VERSION ""

NS_ :

BS_:

BU_:

BO_ 3221225472 VECTOR__INDEPENDENT_SIG_MSG: 0 Vector__XXX
 SG_ New_Signal_146 : 0|8@1+ (1,0) [0|0] "" Vector__XXX
 SG_ New_Signal_145 : 0|8@1+ (1,0) [0|0] "" Vector__XXX
 SG_ New_Signal_144 : 0|8@1+ (1,0) [0|0] "" Vector__XXX
 SG_ New_Signal_143 : 0|8@1+ (1,0) [0|0] "" Vector__XXX
 SG_ New_Signal_139 : 0|8@1+ (1,0) [0|0] "" Vector__XXX
 SG_ New_Signal_138 : 0|8@1+ (1,0) [0|0] "" Vector__XXX
 SG_ New_Signal_120 : 0|8@1+ (1,0) [0|0] "" Vector__XXX
 SG_ New_Signal_55 : 0|8@1+ (1,0) [0|0] "" Vector__XXX
 SG_ Delta_V : 0|16@1+ (1,0) [0|65535] "" Vector__XXX

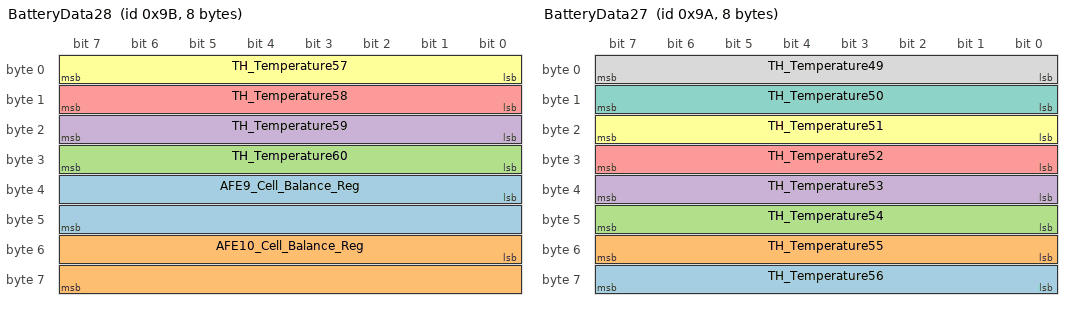
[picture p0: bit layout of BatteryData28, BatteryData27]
BO_ 155 BatteryData28: 8 Vector__XXX
 SG_ AFE9_Cell_Balance_Reg : 32|16@1+ (1,0) [0|65535] "" Vector__XXX
 SG_ AFE10_Cell_Balance_Reg : 48|16@1+ (1,0) [0|65535] "" Vector__XXX
 SG_ TH_Temperature60 : 31|8@0- (1,0) [-128|127] "degC" Vector__XXX
 SG_ TH_Temperature59 : 23|8@0- (1,0) [-128|127] "degC" Vector__XXX
 SG_ TH_Temperature58 : 15|8@0- (1,0) [-128|127] "degC" Vector__XXX
 SG_ TH_Temperature57 : 7|8@0- (1,0) [-128|127] "degC" Vector__XXX

BO_ 154 BatteryData27: 8 Vector__XXX
 SG_ TH_Temperature56 : 63|8@0- (1,0) [-128|127] "degC" Vector__XXX
 SG_ TH_Temperature55 : 55|8@0- (1,0) [-128|127] "degC" Vector__XXX
 SG_ TH_Temperature54 : 47|8@0- (1,0) [-128|127] "degC" Vector__XXX
 SG_ TH_Temperature53 : 39|8@0- (1,0) [-128|127] "degC" Vector__XXX
 SG_ TH_Temperature52 : 31|8@0- (1,0) [-128|127] "degC" Vector__XXX
 SG_ TH_Temperature51 : 23|8@0- (1,0) [-128|127] "degC" Vector__XXX
 SG_ TH_Temperature50 : 15|8@0- (1,0) [-128|127] "degC" Vector__XXX
 SG_ TH_Temperature49 : 7|8@0- (1,0) [-128|127] "degC" Vector__XXX

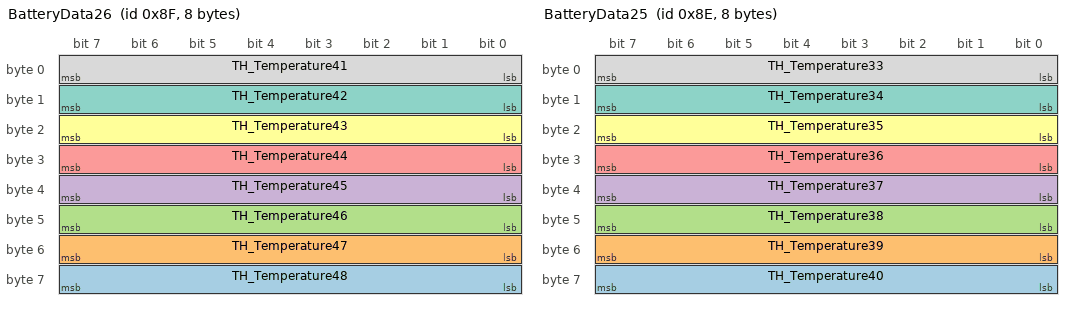
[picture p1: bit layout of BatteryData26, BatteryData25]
BO_ 143 BatteryData26: 8 Vector__XXX
 SG_ TH_Temperature48 : 63|8@0- (1,0) [-128|127] "degC" Vector__XXX
 SG_ TH_Temperature47 : 55|8@0- (1,0) [-128|127] "degC" Vector__XXX
 SG_ TH_Temperature46 : 47|8@0- (1,0) [-128|127] "degC" Vector__XXX
 SG_ TH_Temperature45 : 39|8@0- (1,0) [-128|127] "degC" Vector__XXX
 SG_ TH_Temperature44 : 31|8@0- (1,0) [-128|127] "degC" Vector__XXX
 SG_ TH_Temperature43 : 23|8@0- (1,0) [-128|127] "degC" Vector__XXX
 SG_ TH_Temperature42 : 15|8@0- (1,0) [-128|127] "degC" Vector__XXX
 SG_ TH_Temperature41 : 7|8@0- (1,0) [-128|127] "degC" Vector__XXX

BO_ 142 BatteryData25: 8 Vector__XXX
 SG_ TH_Temperature40 : 63|8@0- (1,0) [-128|127] "degC" Vector__XXX
 SG_ TH_Temperature39 : 55|8@0- (1,0) [-128|127] "degC" Vector__XXX
 SG_ TH_Temperature38 : 47|8@0- (1,0) [-128|127] "degC" Vector__XXX
 SG_ TH_Temperature37 : 39|8@0- (1,0) [-128|127] "degC" Vector__XXX
 SG_ TH_Temperature36 : 31|8@0- (1,0) [-128|127] "degC" Vector__XXX
 SG_ TH_Temperature35 : 23|8@0- (1,0) [-128|127] "degC" Vector__XXX
 SG_ TH_Temperature34 : 15|8@0- (1,0) [-128|127] "degC" Vector__XXX
 SG_ TH_Temperature33 : 7|8@0- (1,0) [-128|127] "degC" Vector__XXX

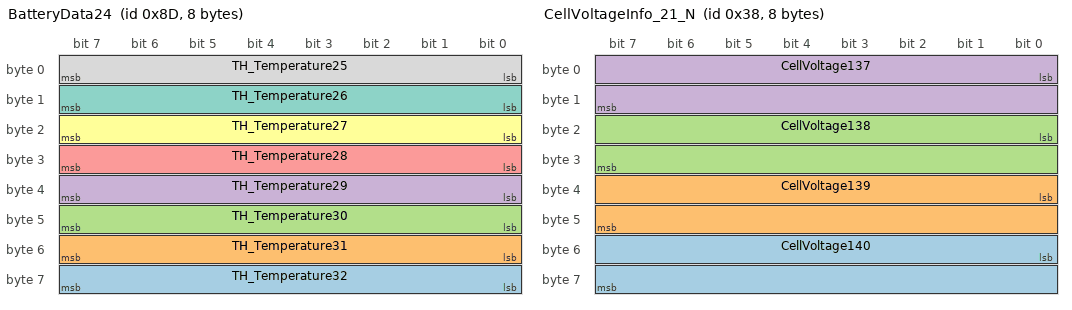
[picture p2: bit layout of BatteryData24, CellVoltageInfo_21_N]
BO_ 141 BatteryData24: 8 Vector__XXX
 SG_ TH_Temperature32 : 63|8@0- (1,0) [-128|127] "degC" Vector__XXX
 SG_ TH_Temperature31 : 55|8@0- (1,0) [-128|127] "degC" Vector__XXX
 SG_ TH_Temperature30 : 47|8@0- (1,0) [-128|127] "degC" Vector__XXX
 SG_ TH_Temperature29 : 39|8@0- (1,0) [-128|127] "degC" Vector__XXX
 SG_ TH_Temperature28 : 31|8@0- (1,0) [-128|127] "degC" Vector__XXX
 SG_ TH_Temperature27 : 23|8@0- (1,0) [-128|127] "degC" Vector__XXX
 SG_ TH_Temperature26 : 15|8@0- (1,0) [-128|127] "degC" Vector__XXX
 SG_ TH_Temperature25 : 7|8@0- (1,0) [-128|127] "degC" Vector__XXX

BO_ 56 CellVoltageInfo_21_N: 8 Vector__XXX
 SG_ CellVoltage140 : 48|16@1+ (0.001,0) [2.7|4.2] "V" Vector__XXX
 SG_ CellVoltage139 : 32|16@1+ (0.001,0) [2.7|4.2] "V" Vector__XXX
 SG_ CellVoltage138 : 16|16@1+ (0.001,0) [2.7|4.2] "V" Vector__XXX
 SG_ CellVoltage137 : 0|16@1+ (0.001,0) [2.7|4.2] "V" Vector__XXX

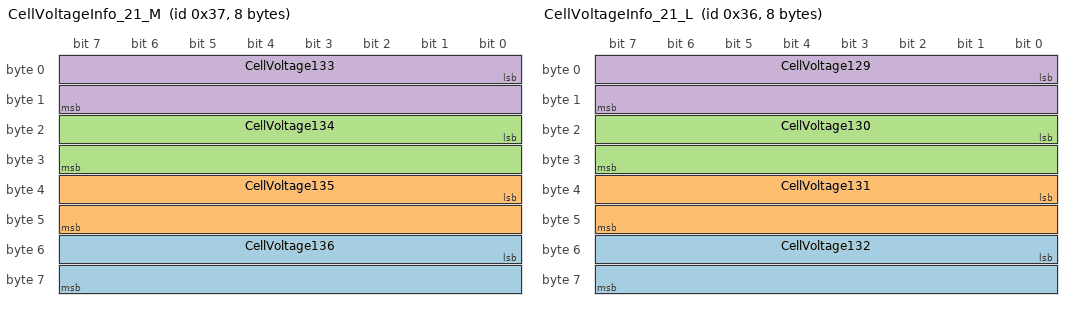
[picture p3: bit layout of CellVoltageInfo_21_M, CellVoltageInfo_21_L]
BO_ 55 CellVoltageInfo_21_M: 8 Vector__XXX
 SG_ CellVoltage136 : 48|16@1+ (0.001,0) [2.7|4.2] "V" Vector__XXX
 SG_ CellVoltage135 : 32|16@1+ (0.001,0) [2.7|4.2] "V" Vector__XXX
 SG_ CellVoltage134 : 16|16@1+ (0.001,0) [2.7|4.2] "V" Vector__XXX
 SG_ CellVoltage133 : 0|16@1+ (0.001,0) [2.7|4.2] "V" Vector__XXX

BO_ 54 CellVoltageInfo_21_L: 8 Vector__XXX
 SG_ CellVoltage132 : 48|16@1+ (0.001,0) [2.7|4.2] "V" Vector__XXX
 SG_ CellVoltage131 : 32|16@1+ (0.001,0) [2.7|4.2] "V" Vector__XXX
 SG_ CellVoltage130 : 16|16@1+ (0.001,0) [2.7|4.2] "V" Vector__XXX
 SG_ CellVoltage129 : 0|16@1+ (0.001,0) [2.7|4.2] "V" Vector__XXX

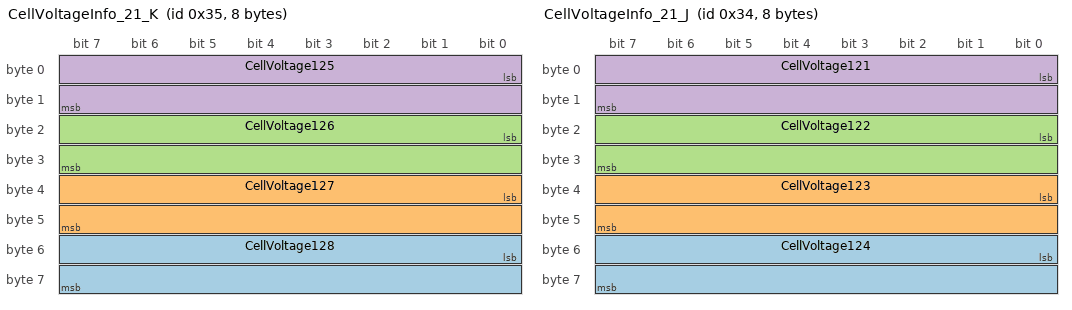
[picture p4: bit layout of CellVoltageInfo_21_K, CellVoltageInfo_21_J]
BO_ 53 CellVoltageInfo_21_K: 8 Vector__XXX
 SG_ CellVoltage128 : 48|16@1+ (0.001,0) [2.7|4.2] "V" Vector__XXX
 SG_ CellVoltage127 : 32|16@1+ (0.001,0) [2.7|4.2] "V" Vector__XXX
 SG_ CellVoltage126 : 16|16@1+ (0.001,0) [2.7|4.2] "V" Vector__XXX
 SG_ CellVoltage125 : 0|16@1+ (0.001,0) [2.7|4.2] "V" Vector__XXX

BO_ 52 CellVoltageInfo_21_J: 8 Vector__XXX
 SG_ CellVoltage124 : 48|16@1+ (0.001,0) [2.7|4.2] "V" Vector__XXX
 SG_ CellVoltage123 : 32|16@1+ (0.001,0) [2.7|4.2] "V" Vector__XXX
 SG_ CellVoltage122 : 16|16@1+ (0.001,0) [2.7|4.2] "V" Vector__XXX
 SG_ CellVoltage121 : 0|16@1+ (0.001,0) [2.7|4.2] "V" Vector__XXX

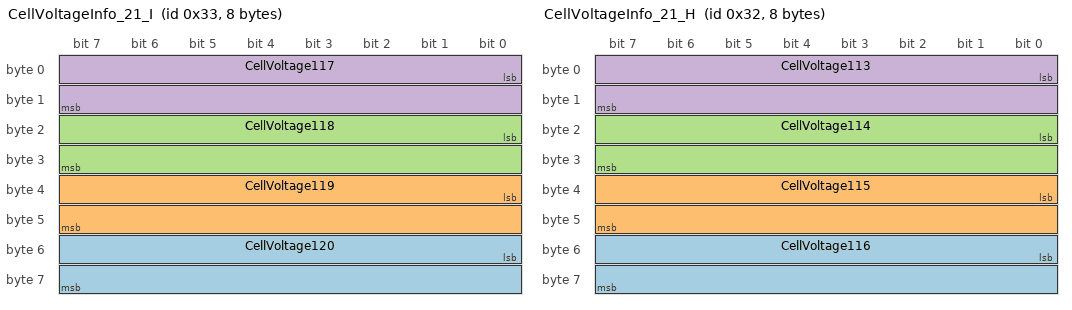
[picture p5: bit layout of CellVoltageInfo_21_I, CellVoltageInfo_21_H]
BO_ 51 CellVoltageInfo_21_I: 8 Vector__XXX
 SG_ CellVoltage120 : 48|16@1+ (0.001,0) [2.7|4.2] "V" Vector__XXX
 SG_ CellVoltage119 : 32|16@1+ (0.001,0) [2.7|4.2] "V" Vector__XXX
 SG_ CellVoltage118 : 16|16@1+ (0.001,0) [2.7|4.2] "V" Vector__XXX
 SG_ CellVoltage117 : 0|16@1+ (0.001,0) [2.7|4.2] "V" Vector__XXX

BO_ 50 CellVoltageInfo_21_H: 8 Vector__XXX
 SG_ CellVoltage116 : 48|16@1+ (0.001,0) [2.7|4.2] "V" Vector__XXX
 SG_ CellVoltage115 : 32|16@1+ (0.001,0) [2.7|4.2] "V" Vector__XXX
 SG_ CellVoltage114 : 16|16@1+ (0.001,0) [2.7|4.2] "V" Vector__XXX
 SG_ CellVoltage113 : 0|16@1+ (0.001,0) [2.7|4.2] "V" Vector__XXX

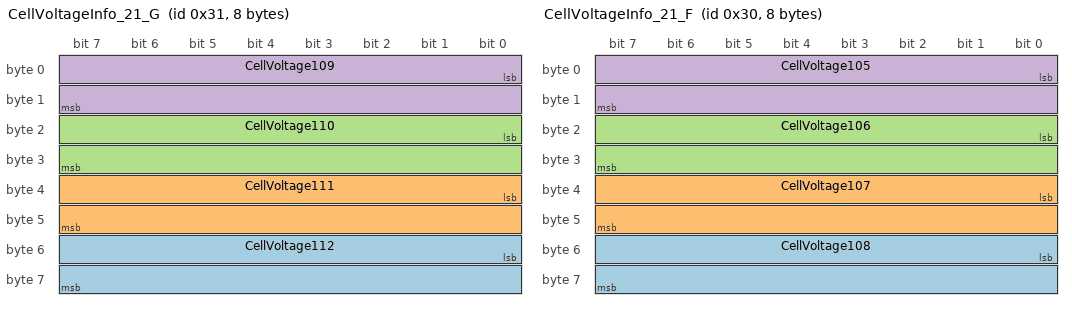
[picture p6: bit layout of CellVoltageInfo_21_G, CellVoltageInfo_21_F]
BO_ 49 CellVoltageInfo_21_G: 8 Vector__XXX
 SG_ CellVoltage112 : 48|16@1+ (0.001,0) [2.7|4.2] "V" Vector__XXX
 SG_ CellVoltage111 : 32|16@1+ (0.001,0) [2.7|4.2] "V" Vector__XXX
 SG_ CellVoltage110 : 16|16@1+ (0.001,0) [2.7|4.2] "V" Vector__XXX
 SG_ CellVoltage109 : 0|16@1+ (0.001,0) [2.7|4.2] "V" Vector__XXX

BO_ 48 CellVoltageInfo_21_F: 8 Vector__XXX
 SG_ CellVoltage108 : 48|16@1+ (0.001,0) [2.7|4.2] "V" Vector__XXX
 SG_ CellVoltage107 : 32|16@1+ (0.001,0) [2.7|4.2] "V" Vector__XXX
 SG_ CellVoltage106 : 16|16@1+ (0.001,0) [2.7|4.2] "V" Vector__XXX
 SG_ CellVoltage105 : 0|16@1+ (0.001,0) [2.7|4.2] "V" Vector__XXX

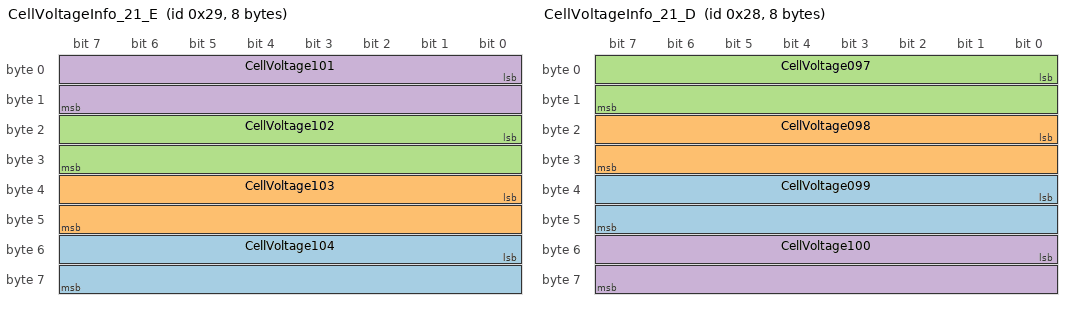
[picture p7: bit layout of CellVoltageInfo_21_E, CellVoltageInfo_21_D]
BO_ 41 CellVoltageInfo_21_E: 8 Vector__XXX
 SG_ CellVoltage104 : 48|16@1+ (0.001,0) [2.7|4.2] "V" Vector__XXX
 SG_ CellVoltage103 : 32|16@1+ (0.001,0) [2.7|4.2] "V" Vector__XXX
 SG_ CellVoltage102 : 16|16@1+ (0.001,0) [2.7|4.2] "V" Vector__XXX
 SG_ CellVoltage101 : 0|16@1+ (0.001,0) [2.7|4.2] "V" Vector__XXX

BO_ 40 CellVoltageInfo_21_D: 8 Vector__XXX
 SG_ CellVoltage099 : 32|16@1+ (0.001,0) [2.7|4.2] "V" Vector__XXX
 SG_ CellVoltage098 : 16|16@1+ (0.001,0) [2.7|4.2] "V" Vector__XXX
 SG_ CellVoltage097 : 0|16@1+ (0.001,0) [2.7|4.2] "V" Vector__XXX
 SG_ CellVoltage100 : 48|16@1+ (0.001,0) [2.7|4.2] "V" Vector__XXX

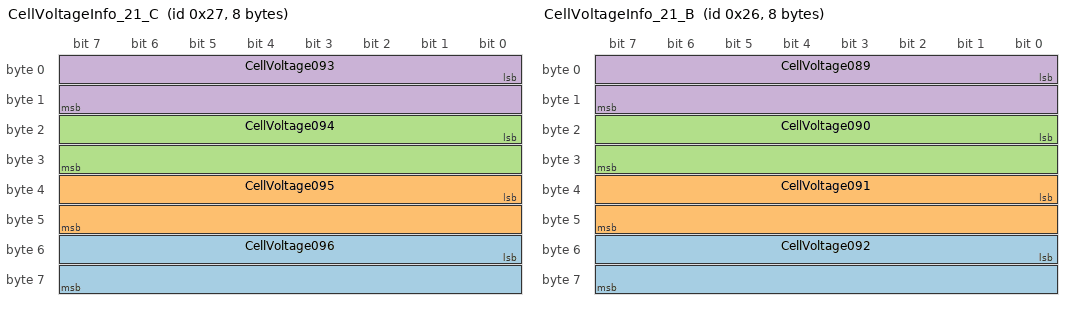
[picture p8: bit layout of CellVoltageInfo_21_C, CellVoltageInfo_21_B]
BO_ 39 CellVoltageInfo_21_C: 8 Vector__XXX
 SG_ CellVoltage096 : 48|16@1+ (0.001,0) [2.7|4.2] "V" Vector__XXX
 SG_ CellVoltage095 : 32|16@1+ (0.001,0) [2.7|4.2] "V" Vector__XXX
 SG_ CellVoltage094 : 16|16@1+ (0.001,0) [2.7|4.2] "V" Vector__XXX
 SG_ CellVoltage093 : 0|16@1+ (0.001,0) [2.7|4.2] "V" Vector__XXX

BO_ 38 CellVoltageInfo_21_B: 8 Vector__XXX
 SG_ CellVoltage092 : 48|16@1+ (0.001,0) [2.7|4.2] "V" Vector__XXX
 SG_ CellVoltage091 : 32|16@1+ (0.001,0) [2.7|4.2] "V" Vector__XXX
 SG_ CellVoltage090 : 16|16@1+ (0.001,0) [2.7|4.2] "V" Vector__XXX
 SG_ CellVoltage089 : 0|16@1+ (0.001,0) [2.7|4.2] "V" Vector__XXX

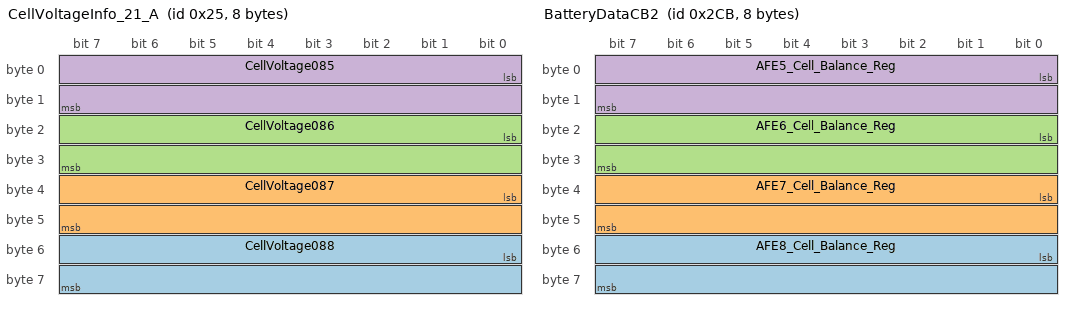
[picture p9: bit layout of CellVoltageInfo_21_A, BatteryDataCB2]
BO_ 37 CellVoltageInfo_21_A: 8 Vector__XXX
 SG_ CellVoltage088 : 48|16@1+ (0.001,0) [2.7|4.2] "V" Vector__XXX
 SG_ CellVoltage087 : 32|16@1+ (0.001,0) [2.7|4.2] "V" Vector__XXX
 SG_ CellVoltage086 : 16|16@1+ (0.001,0) [2.7|4.2] "V" Vector__XXX
 SG_ CellVoltage085 : 0|16@1+ (0.001,0) [2.7|4.2] "V" Vector__XXX

BO_ 715 BatteryDataCB2: 8 Vector__XXX
 SG_ AFE8_Cell_Balance_Reg : 48|16@1+ (1,0) [0|65535] "" Vector__XXX
 SG_ AFE7_Cell_Balance_Reg : 32|16@1+ (1,0) [0|65535] "" Vector__XXX
 SG_ AFE6_Cell_Balance_Reg : 16|16@1+ (1,0) [0|65535] "" Vector__XXX
 SG_ AFE5_Cell_Balance_Reg : 0|16@1+ (1,0) [0|65535] "" Vector__XXX

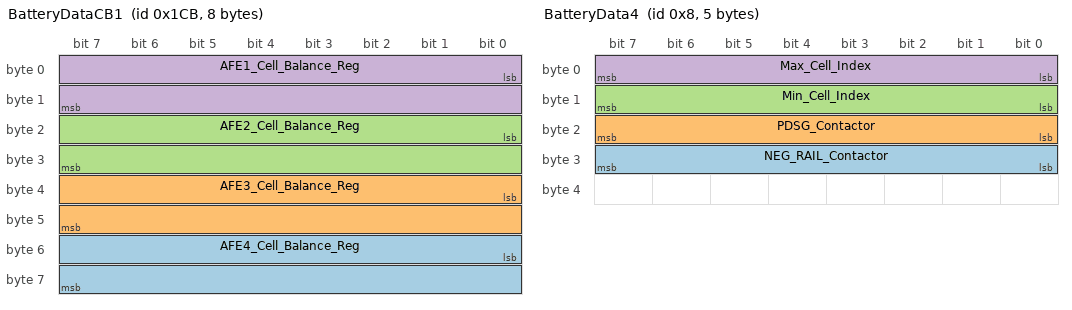
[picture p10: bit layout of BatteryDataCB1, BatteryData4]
BO_ 459 BatteryDataCB1: 8 Vector__XXX
 SG_ AFE4_Cell_Balance_Reg : 48|16@1+ (1,0) [0|65535] "" Vector__XXX
 SG_ AFE3_Cell_Balance_Reg : 32|16@1+ (1,0) [0|65535] "" Vector__XXX
 SG_ AFE2_Cell_Balance_Reg : 16|16@1+ (1,0) [0|65535] "" Vector__XXX
 SG_ AFE1_Cell_Balance_Reg : 0|16@1+ (1,0) [0|65535] "" Vector__XXX

BO_ 8 BatteryData4: 5 Vector__XXX
 SG_ NEG_RAIL_Contactor : 24|8@1+ (1,0) [0|1] "" Vector__XXX
 SG_ PDSG_Contactor : 16|8@1+ (1,0) [0|1] "" Vector__XXX
 SG_ Min_Cell_Index : 8|8@1+ (1,0) [0|100] "" Vector__XXX
 SG_ Max_Cell_Index : 0|8@1+ (1,0) [0|100] "" Vector__XXX

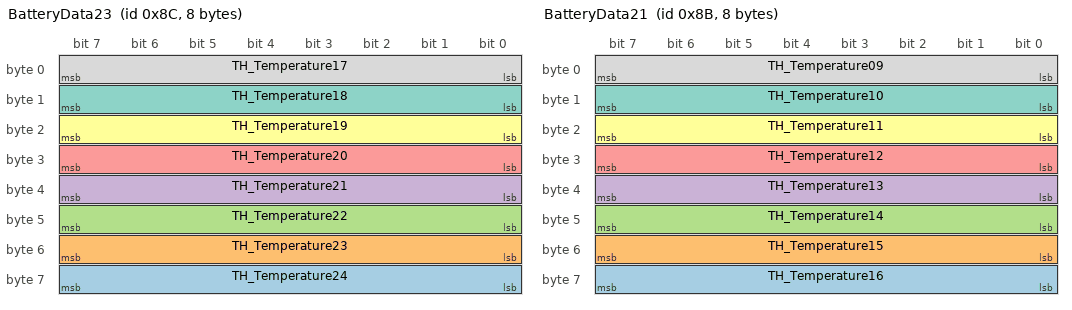
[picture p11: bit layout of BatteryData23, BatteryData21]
BO_ 140 BatteryData23: 8 Vector__XXX
 SG_ TH_Temperature24 : 63|8@0- (1,0) [-128|127] "degC" Vector__XXX
 SG_ TH_Temperature23 : 55|8@0- (1,0) [-128|127] "degC" Vector__XXX
 SG_ TH_Temperature22 : 47|8@0- (1,0) [-128|127] "degC" Vector__XXX
 SG_ TH_Temperature21 : 39|8@0- (1,0) [-128|127] "degC" Vector__XXX
 SG_ TH_Temperature20 : 31|8@0- (1,0) [-128|127] "degC" Vector__XXX
 SG_ TH_Temperature19 : 23|8@0- (1,0) [-128|127] "degC" Vector__XXX
 SG_ TH_Temperature18 : 15|8@0- (1,0) [-128|127] "degC" Vector__XXX
 SG_ TH_Temperature17 : 7|8@0- (1,0) [-128|127] "degC" Vector__XXX

BO_ 139 BatteryData21: 8 Vector__XXX
 SG_ TH_Temperature16 : 63|8@0- (1,0) [-128|127] "degC" Vector__XXX
 SG_ TH_Temperature15 : 55|8@0- (1,0) [-128|127] "degC" Vector__XXX
 SG_ TH_Temperature14 : 47|8@0- (1,0) [-128|127] "degC" Vector__XXX
 SG_ TH_Temperature13 : 39|8@0- (1,0) [-128|127] "degC" Vector__XXX
 SG_ TH_Temperature12 : 24|8@1- (1,0) [-128|127] "degC" Vector__XXX
 SG_ TH_Temperature11 : 23|8@0- (1,0) [-128|127] "degC" Vector__XXX
 SG_ TH_Temperature10 : 15|8@0- (1,0) [-128|127] "degC" Vector__XXX
 SG_ TH_Temperature09 : 7|8@0- (1,0) [-128|127] "degC" Vector__XXX

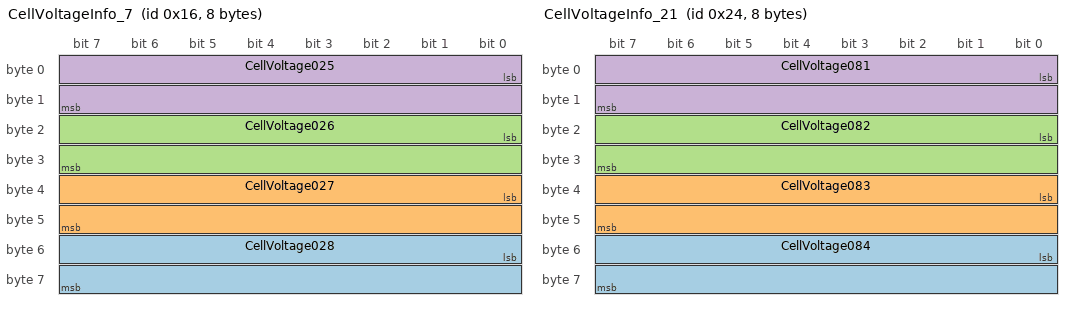
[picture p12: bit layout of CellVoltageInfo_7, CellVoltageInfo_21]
BO_ 22 CellVoltageInfo_7: 8 Vector__XXX
 SG_ CellVoltage028 : 48|16@1+ (0.001,0) [2.7|4.2] "V" Vector__XXX
 SG_ CellVoltage027 : 32|16@1+ (0.001,0) [2.7|4.2] "V" Vector__XXX
 SG_ CellVoltage026 : 16|16@1+ (0.001,0) [2.7|4.2] "V" Vector__XXX
 SG_ CellVoltage025 : 0|16@1+ (0.001,0) [2.7|4.2] "V" Vector__XXX

BO_ 36 CellVoltageInfo_21: 8 Vector__XXX
 SG_ CellVoltage084 : 48|16@1+ (0.001,0) [2.7|4.2] "V" Vector__XXX
 SG_ CellVoltage083 : 32|16@1+ (0.001,0) [2.7|4.2] "V" Vector__XXX
 SG_ CellVoltage082 : 16|16@1+ (0.001,0) [2.7|4.2] "V" Vector__XXX
 SG_ CellVoltage081 : 0|16@1+ (0.001,0) [2.7|4.2] "V" Vector__XXX

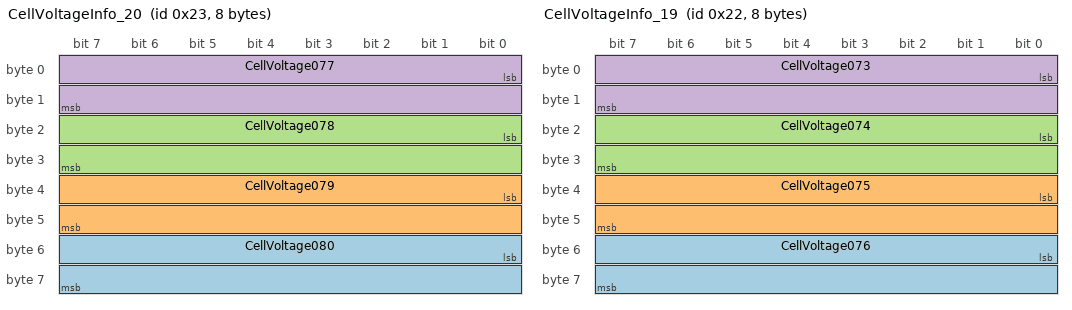
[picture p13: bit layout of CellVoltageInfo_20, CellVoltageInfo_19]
BO_ 35 CellVoltageInfo_20: 8 Vector__XXX
 SG_ CellVoltage080 : 48|16@1+ (0.001,0) [2.7|4.2] "V" Vector__XXX
 SG_ CellVoltage079 : 32|16@1+ (0.001,0) [2.7|4.2] "V" Vector__XXX
 SG_ CellVoltage078 : 16|16@1+ (0.001,0) [2.7|4.2] "V" Vector__XXX
 SG_ CellVoltage077 : 0|16@1+ (0.001,0) [2.7|4.2] "V" Vector__XXX

BO_ 34 CellVoltageInfo_19: 8 Vector__XXX
 SG_ CellVoltage076 : 48|16@1+ (0.001,0) [2.7|4.2] "V" Vector__XXX
 SG_ CellVoltage075 : 32|16@1+ (0.001,0) [2.7|4.2] "V" Vector__XXX
 SG_ CellVoltage074 : 16|16@1+ (0.001,0) [2.7|4.2] "V" Vector__XXX
 SG_ CellVoltage073 : 0|16@1+ (0.001,0) [2.7|4.2] "V" Vector__XXX

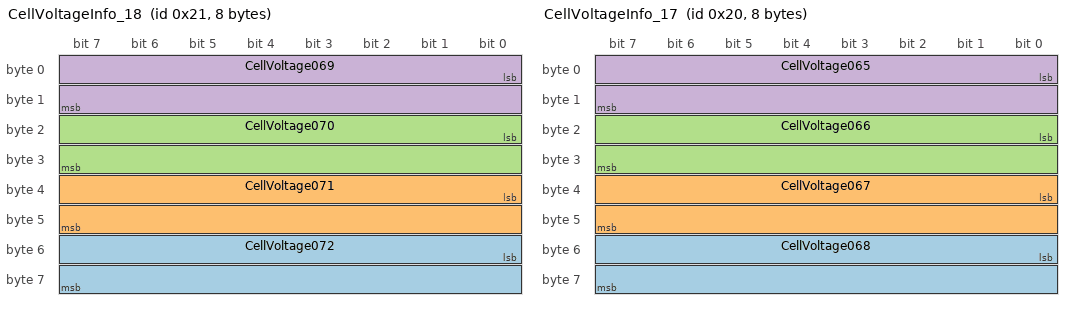
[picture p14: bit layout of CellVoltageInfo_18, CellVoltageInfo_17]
BO_ 33 CellVoltageInfo_18: 8 Vector__XXX
 SG_ CellVoltage072 : 48|16@1+ (0.001,0) [2.7|4.2] "V" Vector__XXX
 SG_ CellVoltage071 : 32|16@1+ (0.001,0) [2.7|4.2] "V" Vector__XXX
 SG_ CellVoltage070 : 16|16@1+ (0.001,0) [2.7|4.2] "V" Vector__XXX
 SG_ CellVoltage069 : 0|16@1+ (0.001,0) [2.7|4.2] "V" Vector__XXX

BO_ 32 CellVoltageInfo_17: 8 Vector__XXX
 SG_ CellVoltage068 : 48|16@1+ (0.001,0) [2.7|4.2] "V" Vector__XXX
 SG_ CellVoltage067 : 32|16@1+ (0.001,0) [2.7|4.2] "V" Vector__XXX
 SG_ CellVoltage066 : 16|16@1+ (0.001,0) [2.7|4.2] "V" Vector__XXX
 SG_ CellVoltage065 : 0|16@1+ (0.001,0) [2.7|4.2] "V" Vector__XXX

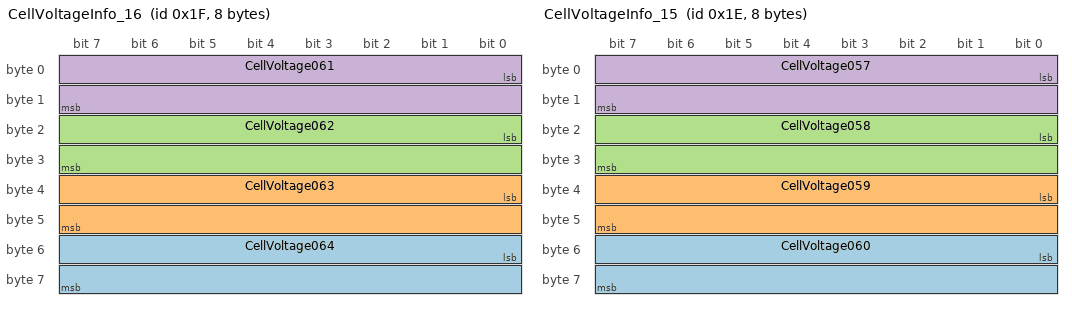
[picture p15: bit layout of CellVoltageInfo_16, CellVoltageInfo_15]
BO_ 31 CellVoltageInfo_16: 8 Vector__XXX
 SG_ CellVoltage064 : 48|16@1+ (0.001,0) [2.7|4.2] "V" Vector__XXX
 SG_ CellVoltage063 : 32|16@1+ (0.001,0) [2.7|4.2] "V" Vector__XXX
 SG_ CellVoltage062 : 16|16@1+ (0.001,0) [2.7|4.2] "V" Vector__XXX
 SG_ CellVoltage061 : 0|16@1+ (0.001,0) [2.7|4.2] "V" Vector__XXX

BO_ 30 CellVoltageInfo_15: 8 Vector__XXX
 SG_ CellVoltage060 : 48|16@1+ (0.001,0) [2.7|4.2] "V" Vector__XXX
 SG_ CellVoltage059 : 32|16@1+ (0.001,0) [2.7|4.2] "V" Vector__XXX
 SG_ CellVoltage058 : 16|16@1+ (0.001,0) [2.7|4.2] "V" Vector__XXX
 SG_ CellVoltage057 : 0|16@1+ (0.001,0) [2.7|4.2] "V" Vector__XXX

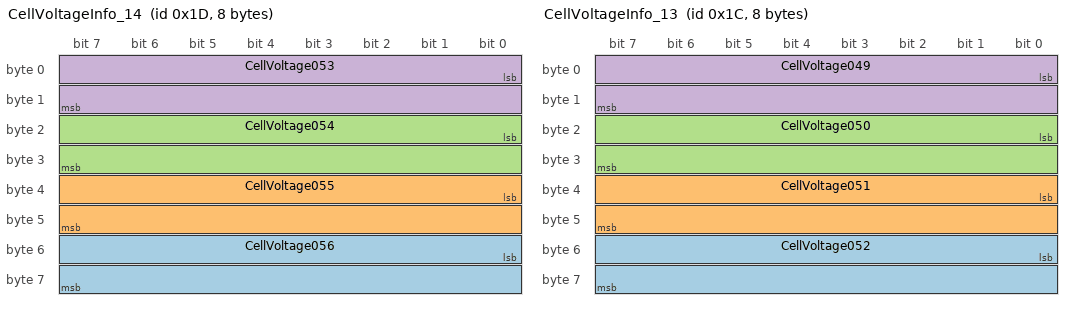
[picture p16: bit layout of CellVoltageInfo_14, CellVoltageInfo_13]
BO_ 29 CellVoltageInfo_14: 8 Vector__XXX
 SG_ CellVoltage056 : 48|16@1+ (0.001,0) [2.7|4.2] "V" Vector__XXX
 SG_ CellVoltage055 : 32|16@1+ (0.001,0) [2.7|4.2] "V" Vector__XXX
 SG_ CellVoltage054 : 16|16@1+ (0.001,0) [2.7|4.2] "V" Vector__XXX
 SG_ CellVoltage053 : 0|16@1+ (0.001,0) [2.7|4.2] "V" Vector__XXX

BO_ 28 CellVoltageInfo_13: 8 Vector__XXX
 SG_ CellVoltage052 : 48|16@1+ (0.001,0) [2.7|4.2] "V" Vector__XXX
 SG_ CellVoltage051 : 32|16@1+ (0.001,0) [2.7|4.2] "V" Vector__XXX
 SG_ CellVoltage050 : 16|16@1+ (0.001,0) [2.7|4.2] "V" Vector__XXX
 SG_ CellVoltage049 : 0|16@1+ (0.001,0) [2.7|4.2] "V" Vector__XXX

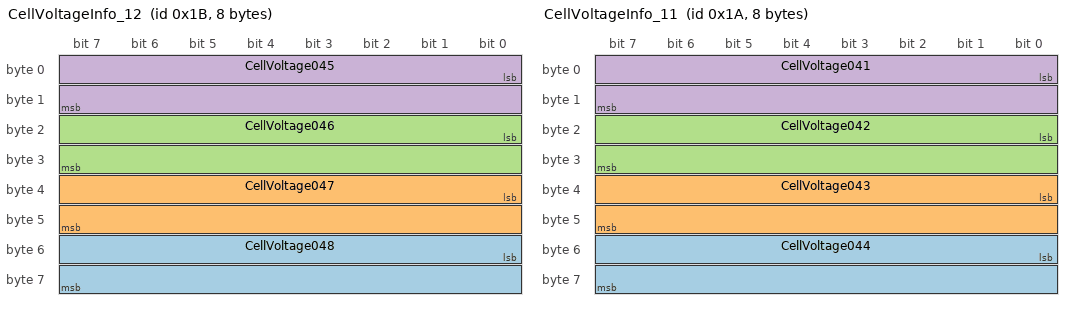
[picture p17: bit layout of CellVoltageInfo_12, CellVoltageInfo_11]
BO_ 27 CellVoltageInfo_12: 8 Vector__XXX
 SG_ CellVoltage048 : 48|16@1+ (0.001,0) [2.7|4.2] "V" Vector__XXX
 SG_ CellVoltage047 : 32|16@1+ (0.001,0) [2.7|4.2] "V" Vector__XXX
 SG_ CellVoltage046 : 16|16@1+ (0.001,0) [2.7|4.2] "V" Vector__XXX
 SG_ CellVoltage045 : 0|16@1+ (0.001,0) [2.7|4.2] "V" Vector__XXX

BO_ 26 CellVoltageInfo_11: 8 Vector__XXX
 SG_ CellVoltage044 : 48|16@1+ (0.001,0) [2.7|4.2] "V" Vector__XXX
 SG_ CellVoltage043 : 32|16@1+ (0.001,0) [2.7|4.2] "V" Vector__XXX
 SG_ CellVoltage042 : 16|16@1+ (0.001,0) [2.7|4.2] "V" Vector__XXX
 SG_ CellVoltage041 : 0|16@1+ (0.001,0) [2.7|4.2] "V" Vector__XXX

BO_ 25 CellVoltageInfo_10: 8 Vector__XXX
 SG_ CellVoltage040 : 48|16@1+ (0.001,0) [2.7|4.2] "V" Vector__XXX
 SG_ CellVoltage039 : 32|16@1+ (0.001,0) [2.7|4.2] "V" Vector__XXX
 SG_ CellVoltage038 : 16|16@1+ (0.001,0) [2.7|4.2] "V" Vector__XXX
 SG_ CellVoltage037 : 0|16@1+ (0.001,0) [2.7|4.2] "V" Vector__XXX

BO_ 24 CellVoltageInfo_9: 8 Vector__XXX
 SG_ CellVoltage036 : 48|16@1+ (0.001,0) [2.7|4.2] "V" Vector__XXX
 SG_ CellVoltage035 : 32|16@1+ (0.001,0) [2.7|4.2] "V" Vector__XXX
 SG_ CellVoltage034 : 16|16@1+ (0.001,0) [2.7|4.2] "V" Vector__XXX
 SG_ CellVoltage033 : 0|16@1+ (0.001,0) [2.7|4.2] "V" Vector__XXX

BO_ 23 CellVoltageInfo_8: 8 Vector__XXX
 SG_ CellVoltage032 : 48|16@1+ (0.001,0) [2.7|4.2] "V" Vector__XXX
 SG_ CellVoltage031 : 32|16@1+ (0.001,0) [2.7|4.2] "V" Vector__XXX
 SG_ CellVoltage030 : 16|16@1+ (0.001,0) [2.7|4.2] "V" Vector__XXX
 SG_ CellVoltage029 : 0|16@1+ (0.001,0) [2.7|4.2] "V" Vector__XXX

BO_ 21 CellVoltageInfo_6: 8 Vector__XXX
 SG_ CellVoltage024 : 48|16@1+ (0.001,0) [2.7|4.2] "V" Vector__XXX
 SG_ CellVoltage023 : 32|16@1+ (0.001,0) [2.7|4.2] "V" Vector__XXX
 SG_ CellVoltage022 : 16|16@1+ (0.001,0) [2.7|4.2] "V" Vector__XXX
 SG_ CellVoltage021 : 0|16@1+ (0.001,0) [2.7|4.2] "V" Vector__XXX

BO_ 20 CellVoltageInfo_5: 8 Vector__XXX
 SG_ CellVoltage020 : 48|16@1+ (0.001,0) [2.7|4.2] "V" Vector__XXX
 SG_ CellVoltage019 : 32|16@1+ (0.001,0) [2.7|4.2] "V" Vector__XXX
 SG_ CellVoltage018 : 16|16@1+ (0.001,0) [2.7|4.2] "V" Vector__XXX
 SG_ CellVoltage017 : 0|16@1+ (0.001,0) [2.7|4.2] "V" Vector__XXX

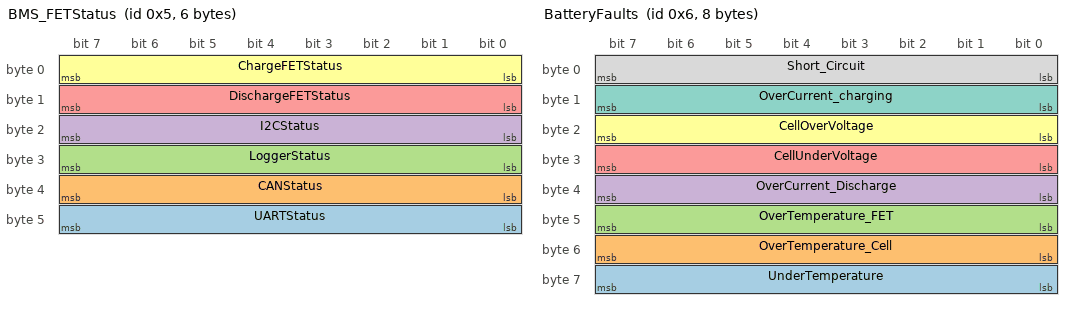
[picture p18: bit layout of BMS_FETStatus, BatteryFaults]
BO_ 5 BMS_FETStatus: 6 Vector__XXX
 SG_ UARTStatus : 47|8@0+ (1,0) [0|0] "" Vector__XXX
 SG_ CANStatus : 39|8@0+ (1,0) [0|0] "" Vector__XXX
 SG_ LoggerStatus : 31|8@0+ (1,0) [0|0] "" Vector__XXX
 SG_ I2CStatus : 23|8@0+ (1,0) [0|0] "" Vector__XXX
 SG_ DischargeFETStatus : 15|8@0+ (1,0) [0|1] "" Vector__XXX
 SG_ ChargeFETStatus : 0|8@1+ (1,0) [0|1] "" Vector__XXX

BO_ 6 BatteryFaults: 8 Vector__XXX
 SG_ UnderTemperature : 63|8@0+ (1,0) [0|0] "" Vector__XXX
 SG_ OverTemperature_Cell : 55|8@0+ (1,0) [0|0] "" Vector__XXX
 SG_ OverTemperature_FET : 47|8@0+ (1,0) [0|0] "" Vector__XXX
 SG_ OverCurrent_Discharge : 39|8@0+ (1,0) [0|0] "" Vector__XXX
 SG_ CellUnderVoltage : 31|8@0+ (1,0) [0|0] "" Vector__XXX
 SG_ CellOverVoltage : 23|8@0+ (1,0) [0|0] "" Vector__XXX
 SG_ OverCurrent_charging : 15|8@0+ (1,0) [0|0] "" Vector__XXX
 SG_ Short_Circuit : 7|8@0+ (1,0) [0|0] "" Vector__XXX

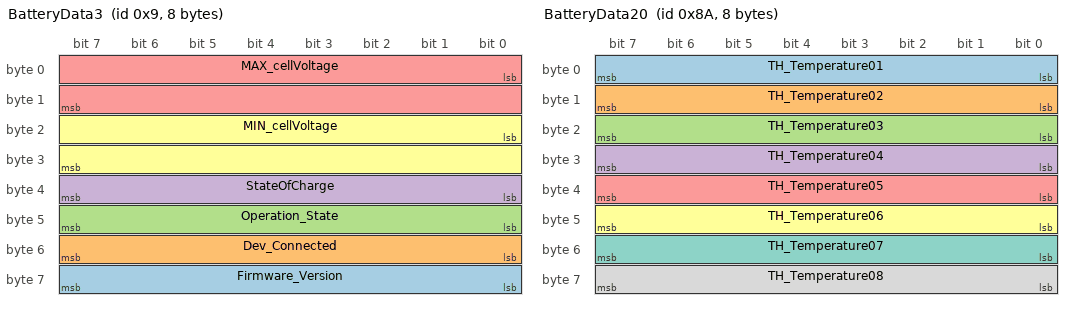
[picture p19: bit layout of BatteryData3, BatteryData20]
BO_ 9 BatteryData3: 8 Vector__XXX
 SG_ Firmware_Version : 56|8@1+ (1,0) [0|255] "" Vector__XXX
 SG_ Dev_Connected : 48|8@1+ (1,0) [0|10] "" Vector__XXX
 SG_ Operation_State : 40|8@1- (1,0) [0|3] "" Vector__XXX
 SG_ StateOfCharge : 32|8@1- (1,0) [0|100] "%" Vector__XXX
 SG_ MAX_cellVoltage : 0|16@1+ (0.001,0) [0|65.535] "V" Vector__XXX
 SG_ MIN_cellVoltage : 16|16@1+ (0.001,0) [0|65.535] "V" Vector__XXX

BO_ 138 BatteryData20: 8 Vector__XXX
 SG_ TH_Temperature01 : 7|8@0+ (1,0) [-128|127] "" Vector__XXX
 SG_ TH_Temperature02 : 15|8@0- (1,0) [-128|127] "degC" Vector__XXX
 SG_ TH_Temperature03 : 23|8@0- (1,0) [-128|127] "degC" Vector__XXX
 SG_ TH_Temperature04 : 31|8@0- (1,0) [-128|127] "degC" Vector__XXX
 SG_ TH_Temperature05 : 39|8@0- (1,0) [-128|127] "degC" Vector__XXX
 SG_ TH_Temperature06 : 47|8@0- (1,0) [-128|127] "degC" Vector__XXX
 SG_ TH_Temperature07 : 55|8@0- (1,0) [-128|127] "degC" Vector__XXX
 SG_ TH_Temperature08 : 63|8@0- (1,0) [-128|127] "degC" Vector__XXX

BO_ 7 BatteryData1: 8 Vector__XXX
 SG_ Cycle_Count : 48|16@1- (1,0) [0|5000] "" Vector__XXX
 SG_ BatteryCapacity : 32|16@1- (1,0) [0|45] "Ah" Vector__XXX
 SG_ Pack_voltage : 16|16@1+ (0.01,0) [0|90] "Volt" Vector__XXX
 SG_ PackCurrent : 0|16@1- (1,0) [-327.68|327.67] "A" Vector__XXX

BO_ 19 CellVoltageInfo_4: 8 Vector__XXX
 SG_ CellVoltage016 : 48|16@1+ (0.001,0) [2.7|4.2] "V" Vector__XXX
 SG_ CellVoltage015 : 32|16@1+ (0.001,0) [2.7|4.2] "V" Vector__XXX
 SG_ CellVoltage014 : 16|16@1+ (0.001,0) [2.7|4.2] "V" Vector__XXX
 SG_ CellVoltage013 : 0|16@1+ (0.001,0) [2.7|4.2] "V" Vector__XXX

BO_ 18 CellVoltageInfo_3: 8 Vector__XXX
 SG_ CellVoltage012 : 48|16@1+ (0.001,0) [2.7|4.2] "V" Vector__XXX
 SG_ CellVoltage011 : 32|16@1+ (0.001,0) [2.7|4.2] "V" Vector__XXX
 SG_ CellVoltage010 : 16|16@1+ (0.001,0) [2.7|4.2] "V" Vector__XXX
 SG_ CellVoltage009 : 0|16@1+ (0.001,0) [2.7|4.2] "V" Vector__XXX

BO_ 17 CellVoltageInfo_2: 8 Vector__XXX
 SG_ CellVoltage008 : 48|16@1+ (0.001,0) [2.7|4.2] "V" Vector__XXX
 SG_ CellVoltage007 : 32|16@1+ (0.001,0) [2.7|4.2] "V" Vector__XXX
 SG_ CellVoltage006 : 16|16@1+ (0.001,0) [2.7|4.2] "V" Vector__XXX
 SG_ CellVoltage005 : 0|16@1+ (0.001,0) [2.7|4.2] "V" Vector__XXX

BO_ 16 CellVoltageInfo_1: 8 Vector__XXX
 SG_ CellVoltage004 : 48|16@1+ (0.001,0) [2.7|4.2] "V" Vector__XXX
 SG_ CellVoltage003 : 32|16@1+ (0.001,0) [2.7|4.2] "V" Vector__XXX
 SG_ CellVoltage002 : 16|16@1+ (0.001,0) [2.7|4.2] "V" Vector__XXX
 SG_ CellVoltage001 : 0|16@1+ (0.001,0) [2.7|4.2] "V" Vector__XXX

CM_ BO_ 3221225472 "This is a message for not used signals, created by Vector CANdb++ DBC OLE DB Provider.";
CM_ SG_ 56 CellVoltage140 "16 bit voltage value of cell 16";
CM_ SG_ 56 CellVoltage139 "16 bit voltage value of cell 16";
CM_ SG_ 56 CellVoltage138 "16 bit voltage value of cell 16";
CM_ SG_ 56 CellVoltage137 "16 bit voltage value of cell 16";
CM_ SG_ 55 CellVoltage136 "16 bit voltage value of cell 16";
CM_ SG_ 55 CellVoltage135 "16 bit voltage value of cell 16";
CM_ SG_ 55 CellVoltage134 "16 bit voltage value of cell 16";
CM_ SG_ 55 CellVoltage133 "16 bit voltage value of cell 16";
CM_ SG_ 54 CellVoltage132 "16 bit voltage value of cell 16";
CM_ SG_ 54 CellVoltage131 "16 bit voltage value of cell 16";
CM_ SG_ 54 CellVoltage130 "16 bit voltage value of cell 16";
CM_ SG_ 54 CellVoltage129 "16 bit voltage value of cell 16";
CM_ SG_ 53 CellVoltage128 "16 bit voltage value of cell 16";
CM_ SG_ 53 CellVoltage127 "16 bit voltage value of cell 16";
CM_ SG_ 53 CellVoltage126 "16 bit voltage value of cell 16";
CM_ SG_ 53 CellVoltage125 "16 bit voltage value of cell 16";
CM_ SG_ 52 CellVoltage124 "16 bit voltage value of cell 16";
CM_ SG_ 52 CellVoltage123 "16 bit voltage value of cell 16";
CM_ SG_ 52 CellVoltage122 "16 bit voltage value of cell 16";
CM_ SG_ 52 CellVoltage121 "16 bit voltage value of cell 16";
CM_ SG_ 51 CellVoltage120 "16 bit voltage value of cell 16";
CM_ SG_ 51 CellVoltage119 "16 bit voltage value of cell 16";
CM_ SG_ 51 CellVoltage118 "16 bit voltage value of cell 16";
CM_ SG_ 51 CellVoltage117 "16 bit voltage value of cell 16";
CM_ SG_ 50 CellVoltage116 "16 bit voltage value of cell 16";
CM_ SG_ 50 CellVoltage115 "16 bit voltage value of cell 16";
CM_ SG_ 50 CellVoltage114 "16 bit voltage value of cell 16";
CM_ SG_ 50 CellVoltage113 "16 bit voltage value of cell 16";
CM_ SG_ 49 CellVoltage112 "16 bit voltage value of cell 16";
CM_ SG_ 49 CellVoltage111 "16 bit voltage value of cell 16";
CM_ SG_ 49 CellVoltage110 "16 bit voltage value of cell 16";
CM_ SG_ 49 CellVoltage109 "16 bit voltage value of cell 16";
CM_ SG_ 48 CellVoltage108 "16 bit voltage value of cell 16";
CM_ SG_ 48 CellVoltage107 "16 bit voltage value of cell 16";
CM_ SG_ 48 CellVoltage106 "16 bit voltage value of cell 16";
CM_ SG_ 48 CellVoltage105 "16 bit voltage value of cell 16";
CM_ SG_ 41 CellVoltage104 "16 bit voltage value of cell 16";
CM_ SG_ 41 CellVoltage103 "16 bit voltage value of cell 16";
CM_ SG_ 41 CellVoltage102 "16 bit voltage value of cell 16";
CM_ SG_ 41 CellVoltage101 "16 bit voltage value of cell 16";
CM_ SG_ 40 CellVoltage099 "16 bit voltage value of cell 16";
CM_ SG_ 40 CellVoltage098 "16 bit voltage value of cell 16";
CM_ SG_ 40 CellVoltage097 "16 bit voltage value of cell 16";
CM_ SG_ 40 CellVoltage100 "16 bit voltage value of cell 16";
CM_ SG_ 39 CellVoltage096 "16 bit voltage value of cell 16";
CM_ SG_ 39 CellVoltage095 "16 bit voltage value of cell 16";
CM_ SG_ 39 CellVoltage094 "16 bit voltage value of cell 16";
CM_ SG_ 39 CellVoltage093 "16 bit voltage value of cell 16";
CM_ SG_ 38 CellVoltage092 "16 bit voltage value of cell 16";
CM_ SG_ 38 CellVoltage091 "16 bit voltage value of cell 16";
CM_ SG_ 38 CellVoltage090 "16 bit voltage value of cell 16";
CM_ SG_ 38 CellVoltage089 "16 bit voltage value of cell 16";
CM_ SG_ 37 CellVoltage088 "16 bit voltage value of cell 16";
CM_ SG_ 37 CellVoltage087 "16 bit voltage value of cell 16";
CM_ SG_ 37 CellVoltage086 "16 bit voltage value of cell 16";
CM_ SG_ 37 CellVoltage085 "16 bit voltage value of cell 16";
CM_ SG_ 22 CellVoltage028 "16 bit voltage value of cell 16";
CM_ SG_ 22 CellVoltage027 "16 bit voltage value of cell 16";
CM_ SG_ 22 CellVoltage026 "16 bit voltage value of cell 16";
CM_ SG_ 22 CellVoltage025 "16 bit voltage value of cell 16";
CM_ SG_ 36 CellVoltage084 "16 bit voltage value of cell 16";
CM_ SG_ 36 CellVoltage083 "16 bit voltage value of cell 16";
CM_ SG_ 36 CellVoltage082 "16 bit voltage value of cell 16";
CM_ SG_ 36 CellVoltage081 "16 bit voltage value of cell 16";
CM_ SG_ 35 CellVoltage080 "16 bit voltage value of cell 16";
CM_ SG_ 35 CellVoltage079 "16 bit voltage value of cell 16";
CM_ SG_ 35 CellVoltage078 "16 bit voltage value of cell 16";
CM_ SG_ 35 CellVoltage077 "16 bit voltage value of cell 16";
CM_ SG_ 34 CellVoltage076 "16 bit voltage value of cell 16";
CM_ SG_ 34 CellVoltage075 "16 bit voltage value of cell 16";
CM_ SG_ 34 CellVoltage074 "16 bit voltage value of cell 16";
CM_ SG_ 34 CellVoltage073 "16 bit voltage value of cell 16";
CM_ SG_ 33 CellVoltage072 "16 bit voltage value of cell 16";
CM_ SG_ 33 CellVoltage071 "16 bit voltage value of cell 16";
CM_ SG_ 33 CellVoltage070 "16 bit voltage value of cell 16";
CM_ SG_ 33 CellVoltage069 "16 bit voltage value of cell 16";
CM_ SG_ 32 CellVoltage068 "16 bit voltage value of cell 16";
CM_ SG_ 32 CellVoltage067 "16 bit voltage value of cell 16";
CM_ SG_ 32 CellVoltage066 "16 bit voltage value of cell 16";
CM_ SG_ 32 CellVoltage065 "16 bit voltage value of cell 16";
CM_ SG_ 31 CellVoltage064 "16 bit voltage value of cell 16";
CM_ SG_ 31 CellVoltage063 "16 bit voltage value of cell 16";
CM_ SG_ 31 CellVoltage062 "16 bit voltage value of cell 16";
CM_ SG_ 31 CellVoltage061 "16 bit voltage value of cell 16";
CM_ SG_ 30 CellVoltage060 "16 bit voltage value of cell 16";
CM_ SG_ 30 CellVoltage059 "16 bit voltage value of cell 16";
CM_ SG_ 30 CellVoltage058 "16 bit voltage value of cell 16";
CM_ SG_ 30 CellVoltage057 "16 bit voltage value of cell 16";
CM_ SG_ 29 CellVoltage056 "16 bit voltage value of cell 16";
CM_ SG_ 29 CellVoltage055 "16 bit voltage value of cell 16";
CM_ SG_ 29 CellVoltage054 "16 bit voltage value of cell 16";
CM_ SG_ 29 CellVoltage053 "16 bit voltage value of cell 16";
CM_ SG_ 28 CellVoltage052 "16 bit voltage value of cell 16";
CM_ SG_ 28 CellVoltage051 "16 bit voltage value of cell 16";
CM_ SG_ 28 CellVoltage050 "16 bit voltage value of cell 16";
CM_ SG_ 28 CellVoltage049 "16 bit voltage value of cell 16";
CM_ SG_ 27 CellVoltage048 "16 bit voltage value of cell 16";
CM_ SG_ 27 CellVoltage047 "16 bit voltage value of cell 16";
CM_ SG_ 27 CellVoltage046 "16 bit voltage value of cell 16";
CM_ SG_ 27 CellVoltage045 "16 bit voltage value of cell 16";
CM_ SG_ 26 CellVoltage044 "16 bit voltage value of cell 16";
CM_ SG_ 26 CellVoltage043 "16 bit voltage value of cell 16";
CM_ SG_ 26 CellVoltage042 "16 bit voltage value of cell 16";
CM_ SG_ 26 CellVoltage041 "16 bit voltage value of cell 16";
CM_ SG_ 25 CellVoltage040 "16 bit voltage value of cell 16";
CM_ SG_ 25 CellVoltage039 "16 bit voltage value of cell 16";
CM_ SG_ 25 CellVoltage038 "16 bit voltage value of cell 16";
CM_ SG_ 25 CellVoltage037 "16 bit voltage value of cell 16";
CM_ SG_ 24 CellVoltage036 "16 bit voltage value of cell 16";
CM_ SG_ 24 CellVoltage035 "16 bit voltage value of cell 16";
CM_ SG_ 24 CellVoltage034 "16 bit voltage value of cell 16";
CM_ SG_ 24 CellVoltage033 "16 bit voltage value of cell 16";
CM_ SG_ 23 CellVoltage032 "16 bit voltage value of cell 16";
CM_ SG_ 23 CellVoltage031 "16 bit voltage value of cell 16";
CM_ SG_ 23 CellVoltage030 "16 bit voltage value of cell 16";
CM_ SG_ 23 CellVoltage029 "16 bit voltage value of cell 16";
CM_ SG_ 21 CellVoltage024 "16 bit voltage value of cell 16";
CM_ SG_ 21 CellVoltage023 "16 bit voltage value of cell 16";
CM_ SG_ 21 CellVoltage022 "16 bit voltage value of cell 16";
CM_ SG_ 21 CellVoltage021 "16 bit voltage value of cell 16";
CM_ SG_ 20 CellVoltage020 "16 bit voltage value of cell 16";
CM_ SG_ 20 CellVoltage019 "16 bit voltage value of cell 16";
CM_ SG_ 20 CellVoltage018 "16 bit voltage value of cell 16";
CM_ SG_ 20 CellVoltage017 "16 bit voltage value of cell 16";
CM_ SG_ 9 MAX_cellVoltage "16 bit voltage value of cell 1";
CM_ SG_ 9 MIN_cellVoltage "16 bit voltage value of cell 1";
CM_ SG_ 19 CellVoltage016 "16 bit voltage value of cell 16";
CM_ SG_ 19 CellVoltage015 "16 bit voltage value of cell 15";
CM_ SG_ 19 CellVoltage014 "16 bit voltage value of cell 14";
CM_ SG_ 19 CellVoltage013 "16 bit voltage value of cell 13";
CM_ SG_ 18 CellVoltage012 "16 bit voltage value of cell 12";
CM_ SG_ 18 CellVoltage011 "16 bit voltage value of cell 11";
CM_ SG_ 18 CellVoltage010 "16 bit voltage value of cell 10";
CM_ SG_ 18 CellVoltage009 "16 bit voltage value of cell 9";
CM_ SG_ 17 CellVoltage008 "16 bit voltage value of cell 8";
CM_ SG_ 17 CellVoltage007 "16 bit voltage value of cell 7";
CM_ SG_ 17 CellVoltage006 "16 bit voltage value of cell 6";
CM_ SG_ 17 CellVoltage005 "16 bit voltage value of cell 5";
CM_ SG_ 16 CellVoltage004 "16 bit voltage value of cell 4";
CM_ SG_ 16 CellVoltage003 "16 bit voltage value of cell 3";
CM_ SG_ 16 CellVoltage002 "16 bit voltage value of cell 2";
CM_ SG_ 16 CellVoltage001 "16 bit voltage value of cell 1";
BA_DEF_  "BusType" STRING ;
BA_DEF_DEF_  "BusType" "CAN";
